# NUC400_v1 register map
File version: 1.0
Registers are 32-bit, read-write, reset 0x0 unless marked. A register's access mark holds for its fields unless they carry their own. Offsets are from the block's base; [hi:lo] are bit positions; {n}, {i} and the like mark numbered series; 'fields as' and 'values as' point back to an identical list.

## ECAP0 — ECAP Register Map
Base 0x400B4000
Same registers: ECAP1 0x400B5000
0x00 ECAP_CNT — Input Capture Counter (24-bit Up Counter)
  [23:0] VAL — Input Capture Timer/Counter. The input Capture Timer/Counter is a 24-bit up-counting counter. The clock source for the counter is from the clock divider output which the CAP_CLK is software optionally divided by 1,4,16 or 32.
{0x4+4i} ECAP_HOLD{i} (i=0..2) — Input Capture Counter Hold Register {i}
  [23:0] VAL — Input Capture Counter Hold Register. When an active input capture channel detects a valid edge signal change, the ECAP_CNT value is latched into the corresponding holding register. Each input channel has itself holding register named by ECAP_HOLDx where x is from 0 to 2 to indicate inputs from IC0 to IC2, respectively.
0x10 ECAP_CNTCMP — Input Capture Counter Compare Register
  [23:0] VAL
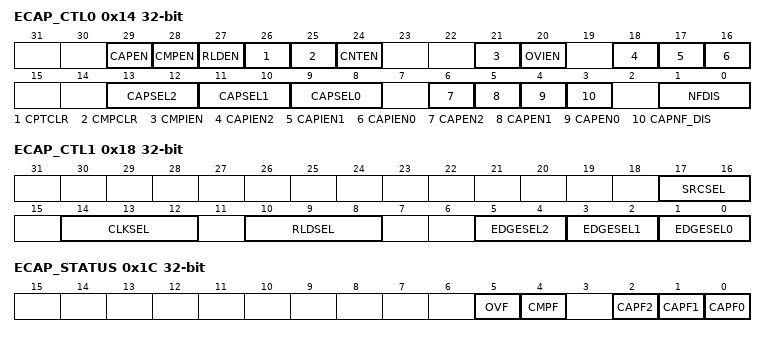
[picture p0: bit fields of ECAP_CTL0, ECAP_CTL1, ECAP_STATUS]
0x14 ECAP_CTL0 — Input Capture Control Register 0
  [29] CAPEN — Input Capture Timer/Counter Enable Bit
    0=Input Capture function Disabled; 1=Input Capture function Enabled
  [28] CMPEN — Compare Function Enable Bit. The compare function in input capture timer/counter is to compare the dynamic counting ECAP_CNT with the compare register ECAP_CNTCMP, if ECAP_CNT value reaches ECAP_CNTCMP, the flag CMPF will be set.
    0=The compare function Disabled; 1=The compare function Enabled
  [27] RLDEN — Reload Function Enable Bit. Setting this bit to enable the reload function. If the reload control is enabled, an overflow event (OVF) or capture events (CAPFx) will trigger the hardware to reload ECAP_CNTCMP into ECAP_CNT.
    0=The reload function Disabled; 1=The reload function Enabled
  [26] CPTCLR — Input Capture Counter Cleared By Capture Events Control. If this bit is set to 1, the capture counter (ECAP_CNT) will be cleared to zero when any one of capture events (CAPF0~3) occurs.
    0=Capture events (CAPF0~3) can clear capture counter (ECAP_CNT) Disabled; 1=Capture events (CAPF0~3) can clear capture counter (ECAP_CNT) Enabled
  [25] CMPCLR — Input Capture Counter Cleared By Compare-Match Control
    0=Compare-match event (CAMCMPF) can clear capture counter (ECAP_CNT) Disabled; 1=Compare-match event (CAMCMPF) can clear capture counter (ECAP_CNT) Enabled
  [24] CNTEN — Input Capture Counter Start. Setting this bit to 1, the capture counter (ECAP_CNT) starts up-counting synchronously with capture clock input (CAP_CLK).
    0=ECAP_CNT stop counting; 1=ECAP_CNT starts up-counting
  [21] CMPIEN — CMPF Trigger Input Capture Interrupt Enable Bit
    0=The flag CMPF can trigger Input Capture interrupt Disabled; 1=The flag CMPF can trigger Input Capture interrupt Enabled
  [20] OVIEN — OVF Trigger Input Capture Interrupt Enable Bit
    0=The flag OVUNF can trigger Input Capture interrupt Disabled; 1=The flag OVUNF can trigger Input Capture interrupt Enabled
  [18] CAPIEN2 — Input Capture Channel 2 Interrupt Enable Bit
    0=The flag CAPF2 can trigger Input Capture interrupt Disabled; 1=The flag CAPF2 can trigger Input Capture interrupt Enabled
  [17] CAPIEN1 — Input Capture Channel 1 Interrupt Enable Bit
    0=The flag CAPF1 can trigger Input Capture interrupt Disabled; 1=The flag CAPF1 can trigger Input Capture interrupt Enabled
  [16] CAPIEN0 — Input Capture Channel 0 Interrupt Enable Bit
    0=The flag CAPF0 can trigger Input Capture interrupt Disabled; 1=The flag CAPF0 can trigger Input Capture interrupt Enabled
  [13:12] CAPSEL2 — CAP2 Input Source Selection
    0=CAP2 input is from port pin IC2; 1=CAP2 input is from signal CPO2 (Analog comparator 2 output); 2=CAP2 input is from signal CHX of QEI controller unit x; 3=CAP2 input is from signal ADCMPOx (ADC compare output x)
  [11:10] CAPSEL1 — CAP1 Input Source Selection
    0=CAP1 input is from port pin IC1; 1=CAP1 input is from signal CPO1 (Analog comparator 1 output); 2=CAP1 input is from signal CHB of QEI controller unit x; 3=CAP1 input is from signal OPDO1 (OP1 digital output)
  [9:8] CAPSEL0 — CAP0 Input Source Selection
    0=CAP0 input is from port pin IC0; 1=CAP0 input is from signal CPO0 (Analog comparator 0 output); 2=CAP0 input is from signal CHA of QEI controller unit x; 3=CAP0 input is from signal OPDO0 (OP0 digital output)
  [6] CAPEN2 — Port Pin IC2 Input To Input Capture Unit Enable Bit
    0=IC2 input to Input Capture Unit Disabled; 1=IC2 input to Input Capture Unit Enabled
  [5] CAPEN1 — Port Pin IC1 Input To Input Capture Unit Enable Bit
    0=IC1 input to Input Capture Unit Disabled; 1=IC1 input to Input Capture Unit Enabled
  [4] CAPEN0 — Port Pin IC0 Input To Input Capture Unit Enable Bit
    0=IC0 input to Input Capture Unit Disabled; 1=IC0 input to Input Capture Unit Enabled
  [3] CAPNF_DIS — Input Capture Noise Filter Disable Bit
    0=Noise filter of Input Capture Enabled; 1=Noise filter of Input Capture Disabled
  [1:0] NFDIS — Noise Filter Clock Pre-Divide Selection. To determine the sampling frequency of the Noise Filter clock
    0=CAP_CLK; 1=CAP_CLK/2; 2=CAP_CLK/4; 3=CAP_CLK/16
0x18 ECAP_CTL1 — Input Capture Control Register 1
  [17:16] SRCSEL — Capture Timer/Counter Clock Source Selection. Select the capture timer/counter clock source.
    0=CAP_CLK (default); 1=CAP0; 2=CAP1; 3=CAP2
  [14:12] CLKSEL — Capture Timer Clock Divide Selection. The capture timer clock has a pre-divider with eight divided options controlled by CLKSEL[1:0].
    0=CAP_CLK/1; 1=CAP_CLK/4; 2=CAP_CLK/16; 3=CAP_CLK/32; 4=CAP_CLK/64; 5=CAP_CLK/96; 6=CAP_CLK/112; 7=CAP_CLK/128
  [10:8] RLDSEL — ECAP_CNT Reload Trigger Source Selection
    0=CAPF0; 1=CAPF1; 2=CAPF2; 4=OVF
  [5:4] EDGESEL2 — Channel 2 Captured Edge Selection. Input capture can detect falling edge change or rising edge change only, or one of both edge changes.
    0=Detect rising edge; 1=Detect falling edge. Detect either rising or falling edge
  [3:2] EDGESEL1 — Channel 1 Captured Edge Selection. Input capture can detect falling edge change only, rising edge change only or one of both edge change
    values as EDGESEL2
  [1:0] EDGESEL0 — Channel 0 Captured Edge Selection. Input capture can detect falling edge change only, rising edge change only or one of both edge change
    values as EDGESEL2
0x1C ECAP_STATUS — Input Capture Status Register
  [5] OVF — Input Capture Counter Overflow Flag. Flag is set by hardware when input capture up counter (ECAP_CNT) overflows from 0x00FF_FFFF to zero. Note: This bit is only cleared by writing 1 to it.
    0=No overflow occurs in ECAP_CNT; 1=ECAP_CNT overflows
  [4] CMPF — Input Capture Compare-Match Flag. If the input capture compare function is enabled, the flag is set by hardware while capture counter (ECAP_CNT) up counts and reach to the ECAP_CNTCMP value. Note: This bit is only cleared by writing 1 to it.
    0=ECAP_CNT does not match with ECAP_CNTCMP value; 1=ECAP_CNT counts to the same as ECAP_CNTCMP value
  [2] CAPF2 — Input Capture Channel 2 Captured Flag. When the input capture channel 2 detects a valid edge change at CAP2 input, it will set flag CAPF2 to high. Note: This bit is only cleared by writing 1 to it.
    0=No valid edge change is detected at CAP2 input; 1=A valid edge change is detected at CAP2 input
  [1] CAPF1 — Input Capture Channel 1 Captured Flag. When the input capture channel 1 detects a valid edge change at CAP1 input, it will set flag CAPF1 to high. Note: This bit is only cleared by writing 1 to it.
    0=No valid edge change is detected at CAP1 input; 1=A valid edge change is detected at CAP1 input
  [0] CAPF0 — Input Capture Channel 0 Captured Flag. When the input capture channel 0 detects a valid edge change at CAP0 input, it will set flag CAPF0 to high. Note: This bit is only cleared by writing 1 to it.
    0=No valid edge change is detected at CAP0 input; 1=A valid edge change is detected at CAP0 input
